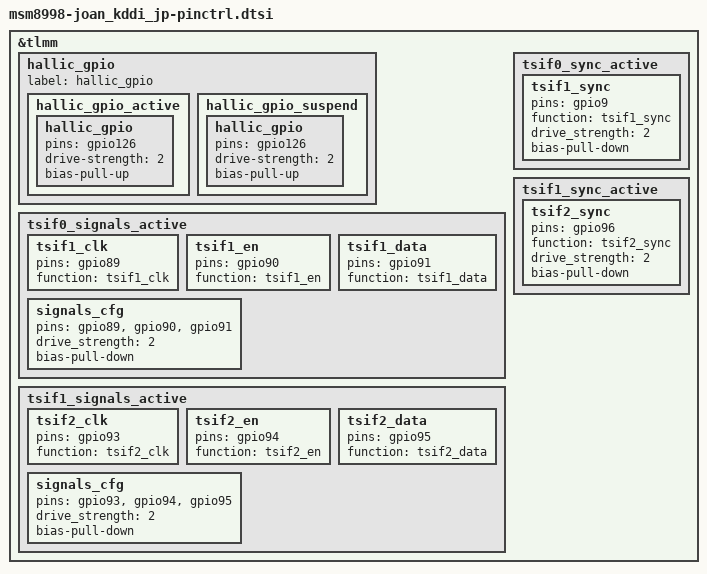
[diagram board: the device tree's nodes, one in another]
/* Copyright (c) 2015-2016, The Linux Foundation. All rights reserved.
 *
 * This program is free software; you can redistribute it and/or modify
 * it under the terms of the GNU General Public License version 2 and
 * only version 2 as published by the Free Software Foundation.
 *
 * This program is distributed in the hope that it will be useful,
 * but WITHOUT ANY WARRANTY; without even the implied warranty of
 * MERCHANTABILITY or FITNESS FOR A PARTICULAR PURPOSE.  See the
 * GNU General Public License for more details.
 */

#include "../msm8998-joan-common/msm8998-joan-common-pinctrl.dtsi"

&tlmm {
	/delete-node/ i2c_2;
	/delete-node/ spi_2;
	/delete-node/ blsp1_uart2_active;
	/delete-node/ blsp1_uart2_sleep;

	/* pin set for Hall IC */
	hallic_gpio {
		label = "hallic_gpio";
		hallic_gpio_active: hallic_gpio_active {
			hallic_gpio {
				pins = "gpio126";
				drive-strength = <2>;
				bias-pull-up;
			};
		};
		hallic_gpio_suspend: hallic_gpio_suspend {
			hallic_gpio {
				pins = "gpio126";
				drive-strength = <2>;
				bias-pull-up;
			};
		};
	};

	// [S][DTV] TSPP for DTV
	tsif0_signals_active: tsif0_signals_active {
		tsif1_clk {
			pins = "gpio89"; /* TSIF0 CLK */
			function = "tsif1_clk";
		};

		tsif1_en {
			pins = "gpio90"; /* TSIF0 Enable */
			function = "tsif1_en";
		};

		tsif1_data {
			pins = "gpio91"; /* TSIF0 DATA */
			function = "tsif1_data";
		};

		signals_cfg {
			pins = "gpio89", "gpio90", "gpio91";
			drive_strength = <2>; /* 2 mA */
			bias-pull-down; /* pull down */
		};
	};

	/* sync signal is only used if configured to mode-2 */
	tsif0_sync_active: tsif0_sync_active {
		tsif1_sync {
			pins = "gpio9"; /* TSIF0 SYNC */
			function = "tsif1_sync";
			drive_strength = <2>; /* 2 mA */
			bias-pull-down; /* pull down */
		};
	};

	tsif1_signals_active: tsif1_signals_active {
		tsif2_clk {
			pins = "gpio93"; /* TSIF1 CLK */
			function = "tsif2_clk";
		};
		tsif2_en {
			pins = "gpio94"; /* TSIF1 Enable */
			function = "tsif2_en";
		};
		tsif2_data {
			pins = "gpio95"; /* TSIF1 DATA */
			function = "tsif2_data";
		};
		signals_cfg {
			pins = "gpio93", "gpio94", "gpio95";
			drive_strength = <2>;	/* 2 mA */
			bias-pull-down;		/* pull down */
		};
	};

	/* sync signal is only used if configured to mode-2 */
	tsif1_sync_active: tsif1_sync_active {
		tsif2_sync {
			pins = "gpio96";	/* TSIF1 SYNC */
			function = "tsif2_sync";
			drive_strength = <2>;	/* 2 mA */
			bias-pull-down;		/* pull down */
		};
	};
	// [E][DTV] TSPP for DTV
};
